# SA3_SS_SEC_PROXY_0_SEC_PROXY_SCFG_44860000h register map
Vendor: Texas Instruments
Peripheral module from a debugger description file (folder AM275x).
Registers are 32-bit, read-write, reset 0x0 unless marked. A register's access mark holds for its fields unless they carry their own. Offsets are as the file gives them; lines under a group give offsets from that group; [hi:lo] are bit positions; {n}, {i} and the like mark numbered series; 'fields as' and 'values as' point back to an identical list; <NAME> marks a mode.

## sec_proxy_scfg
0x00 SEC_PROXY_SCFG_BUFFER_L — The Buffer Register defines the pointer for the external buffer.
  [31:0] BASE_L — The base address for the external buffer, lower 32 bits. Reset Source: rst_mod_g_rst_n
0x04 SEC_PROXY_SCFG_BUFFER_H — The Buffer Register defines the pointer for the external buffer.
  [15:0] BASE_H — The base address for the external buffer, upper 16 bits. Reset Source: rst_mod_g_rst_n
0x08 SEC_PROXY_SCFG_TARGET_L reset 0x400000 — The Target Register defines the pointer for the external target.
  [31:0] BASE_L — The base address for the external target, lower 32 bits. Reset Source: rst_mod_g_rst_n
0x0C SEC_PROXY_SCFG_TARGET_H — The Target Register defines the pointer for the external target.
  [15:0] BASE_H — The base address for the external target, upper 16 bits. Reset Source: rst_mod_g_rst_n
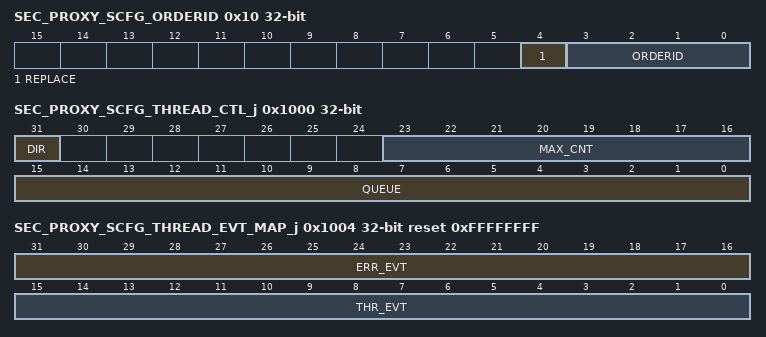
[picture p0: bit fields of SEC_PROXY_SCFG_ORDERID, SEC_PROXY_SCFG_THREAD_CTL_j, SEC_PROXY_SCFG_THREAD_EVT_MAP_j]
0x10 SEC_PROXY_SCFG_ORDERID — The Buffer OrderID Register contains the bus orderid value for the buffer memory access.
  [4] REPLACE — Indicates to replace the bus orderid value for the buffer access with the orderid MMR field. This allows control over the orderid value when it must be restricted due to the topology for QoS reasons. 0 = bypass and use the orderid from the source transaction for the destination transaction. 1 = use the orderid MMR field value for the destination transaction. Reset Source: rst_mod_g_rst_n
  [3:0] ORDERID — Defines the bus orderid value for the buffer access. Reset Source: rst_mod_g_rst_n
0x1000 SEC_PROXY_SCFG_THREAD_CTL_j — The Control Register defines controls for proxy thread a.
  [31] DIR — Direction for the proxy thread. 0 = outbound, write only. 1 = inbound, read only. Reset Source: rst_mod_g_rst_n
  [23:16] MAX_CNT — Max message count allowed for an outbound proxy thread. Is not used otherwise. Reset Source: rst_mod_g_rst_n
  [15:0] QUEUE — Queue number in the target to use for the proxy thread. If the target base does not start at queue 0 then this is the relative queue number from that base queue. Reset Source: rst_mod_g_rst_n
0x1004 SEC_PROXY_SCFG_THREAD_EVT_MAP_j reset 0xFFFFFFFF — The Event Map Register defines the event numbers for proxy thread a.
  [31:16] ERR_EVT — Event number for an error from the proxy thread. Reset Source: rst_mod_g_rst_n
  [15:0] THR_EVT — Event number for a threshold event from the proxy thread. Reset Source: rst_mod_g_rst_n
0x1008 SEC_PROXY_SCFG_THREAD_DST_j — The Destination Register defines the destination proxy thread for outbound proxy thread a.
  [15:0] THREAD — The proxy thread that is the destination of messages from this outbound proxy thread, based on the queue numbers. This is ignored for inbound proxy threads. Reset Source: rst_mod_g_rst_n
